# ADSP-2183xW_HPC register map
Vendor: Analog Devices; Series: ADSP-2183xW_HPC; File version: 3.0.3.517
CPU: 
Registers are 32-bit, read-write, reset 0x0 unless marked. A register's access mark holds for its fields unless they carry their own. Offsets are from the block's base; [hi:lo] are bit positions.

## FRACNPLL — The Fractional Phase-locked loop
Base 0x31144000
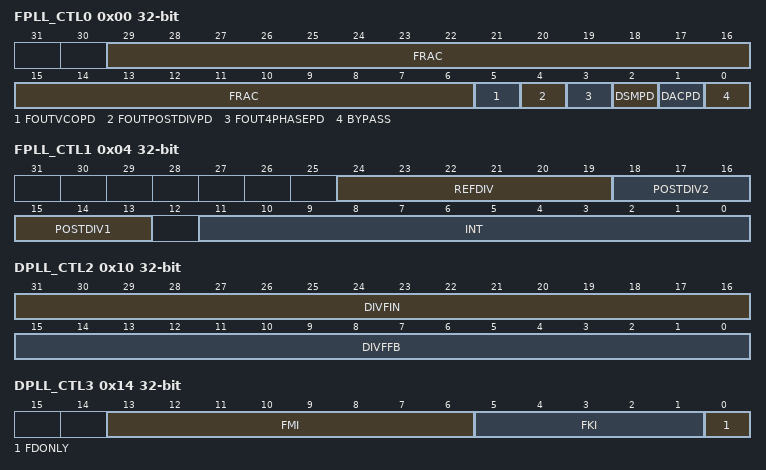
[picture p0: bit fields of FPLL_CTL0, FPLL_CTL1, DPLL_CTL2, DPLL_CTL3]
0x00 FPLL_CTL0 — Frac PLL Control Register 0
  [29:6] FRAC range 0x00000000..0x00FFFFFF — Frac PLL FRAC Control
  [5] FOUTVCOPD range 0x00000000..0x00000001 — Frac PLL FOUTVCOPD Control
  [4] FOUTPOSTDIVPD range 0x00000000..0x00000001 — Frac PLL FOUTPOSTDIVPD Control
  [3] FOUT4PHASEPD range 0x00000000..0x00000001 — Frac PLL FOUT4PHASEPD Control
  [2] DSMPD range 0x00000000..0x00000001 — Frac PLL DSMPD Control
  [1] DACPD range 0x00000000..0x00000001 — Frac PLL DACPD Control
  [0] BYPASS range 0x00000000..0x00000001 — Frac PLL BYPASS Control
0x04 FPLL_CTL1 — Frac PLL Control Register 1
  [24:19] REFDIV range 0x00000000..0x0000003F — Frac PLL REFDIV Control
  [18:16] POSTDIV2 range 0x00000000..0x00000007 — Frac PLL POSTDIV2 Control
  [15:13] POSTDIV1 range 0x00000000..0x00000007 — Frac PLL POSTDIV1 Control
  [11:0] INT range 0x00000000..0x00000FFF — Frac PLL FBDIV Control
0x08 DPLL_CTL0 — DPLL Control Register 0
  [15:0] CNTOFFSET range 0x00000000..0x0000FFFF — DPLL CNTOFFSET Control
0x0C DPLL_CTL1 — DPLL Control Register 1
  [23:0] DELAYK range 0x00000000..0x00FFFFFF — DPLL DELAYK Control
0x10 DPLL_CTL2 — DPLL Control Register 2
  [31:16] DIVFIN range 0x00000000..0x0000FFFF — DPLL DIVFIN Control
  [15:0] DIVFFB range 0x00000000..0x0000FFFF — DPLL DIVFFB Control
0x14 DPLL_CTL3 — DPLL Control Register 3
  [13:6] FMI range 0x00000000..0x000000FF — DPLL FMI Control
  [5:1] FKI range 0x00000000..0x0000001F — DPLL FKI Control
  [0] FDONLY range 0x00000000..0x00000001 — DPLL FDONLY Control
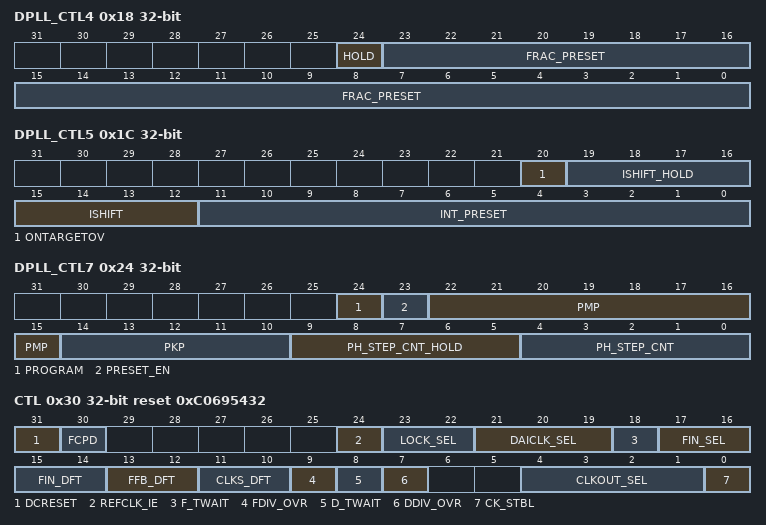
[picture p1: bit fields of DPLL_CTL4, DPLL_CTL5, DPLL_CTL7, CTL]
0x18 DPLL_CTL4 — DPLL Control Register 4
  [24] HOLD range 0x00000000..0x00000001 — DPLL HOLD Control
  [23:0] FRAC_PRESET range 0x00000000..0x00FFFFFF — DPLL FRAC_PRESET Control
0x1C DPLL_CTL5 — DPLL Control Register 5
  [20] ONTARGETOV range 0x00000000..0x00000001 — DPLL ONTARGETOV Control
  [19:16] ISHIFT_HOLD range 0x00000000..0x0000000F — DPLL ISHIFT_HOLD Control
  [15:12] ISHIFT range 0x00000000..0x0000000F — DPLL ISHIFT Control
  [11:0] INT_PRESET range 0x00000000..0x00000FFF — DPLL INT_PRESET Control
0x20 DPLL_CTL6 — DPLL Control Register 6
  [15:0] OTDLY range 0x00000000..0x0000FFFF — DPLL OTDLY Control
0x24 DPLL_CTL7 — DPLL Control Register 7
  [24] PROGRAM range 0x00000000..0x00000001 — DPLL PROGRAM Control
  [23] PRESET_EN range 0x00000000..0x00000001 — DPLL PRESET_EN Control
  [22:15] PMP range 0x00000000..0x000000FF — DPLL PMP Control
  [14:10] PKP range 0x00000000..0x0000001F — DPLL PKP Control
  [9:5] PH_STEP_CNT_HOLD range 0x00000000..0x0000001F — DPLL PH_STEP_CNT_HOLD Control
  [4:0] PH_STEP_CNT range 0x00000000..0x0000001F — DPLL PH_STEP_CNT Control
0x28 DPLL_CTL8 — DPLL Control Register 8
  [31:0] SYNCCNTMAX range 0x00000000..0xFFFFFFFF — DPLL SYNCCNTMAX Control
0x2C DPLL_CTL9 — DPLL Control Register 9
  [15:0] TARGETCNT range 0x00000000..0x0000FFFF — DPLL TARGETCNT Control
0x30 CTL reset 0xC0695432 — Integration Control Register
  [31] DCRESET range 0x00000000..0x00000001 — DPLL RESET Control
  [30] FCPD range 0x00000000..0x00000001 — Frac PLL PD Control
  [24] REFCLK_IE range 0x00000000..0x00000001 — Reference Clock Enable
  [23:22] LOCK_SEL range 0x00000000..0x00000003 — FLOCK F/PLOCK Select
  [21:19] DAICLK_SEL range 0x00000000..0x00000007 — DAI Clock Select
  [18] F_TWAIT range 0x00000000..0x00000001 — Frac PLL Trigger Wait
  [17:16] FIN_SEL range 0x00000000..0x00000003 — External Reference Clock Select
  [15:14] FIN_DFT range 0x00000000..0x00000003 — FIN DFT Mode
  [13:12] FFB_DFT range 0x00000000..0x00000003 — FFB DFT Mode
  [11:10] CLKS_DFT range 0x00000000..0x00000003 — CLKS DFT Mode
  [9] FDIV_OVR range 0x00000000..0x00000001 — Fractional Divider Overdrive
  [8] D_TWAIT range 0x00000000..0x00000001 — DPLL I/P Trigger Wait
  [7] DDIV_OVR range 0x00000000..0x00000001 — Integer Divider Overdrive
  [4:1] CLKOUT_SEL range 0x00000000..0x0000000F — Frac PLL Clock Select
  [0] CK_STBL range 0x00000000..0x00000001 — Frac PLL CLK Stable
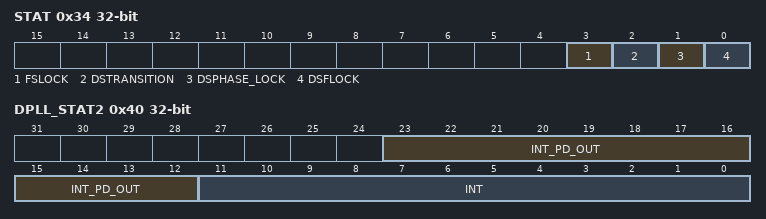
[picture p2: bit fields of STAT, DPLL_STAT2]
0x34 STAT — Integration Status Register
  [3] FSLOCK ro — Frac PLL Freqency Lock
  [2] DSTRANSITION ro — DPLL Transition Status
  [1] DSPHASE_LOCK ro — DPLL Phase Lock Status
  [0] DSFLOCK ro — DPLL Frequency Lock Status
0x38 DPLL_STAT0 — DPLL Status Register 0
  [23:0] FRAC ro — DPLL FRAC Status
0x3C DPLL_STAT1 — DPLL Status Register 1
  [23:0] FRAC_PD_OUT ro — DPLL FRAC_PD_OUT Status
0x40 DPLL_STAT2 — DPLL Status Register 2
  [23:12] INT_PD_OUT ro — DPLL INT_PD_OUT Status
  [11:0] INT ro — DPLL INT Status
